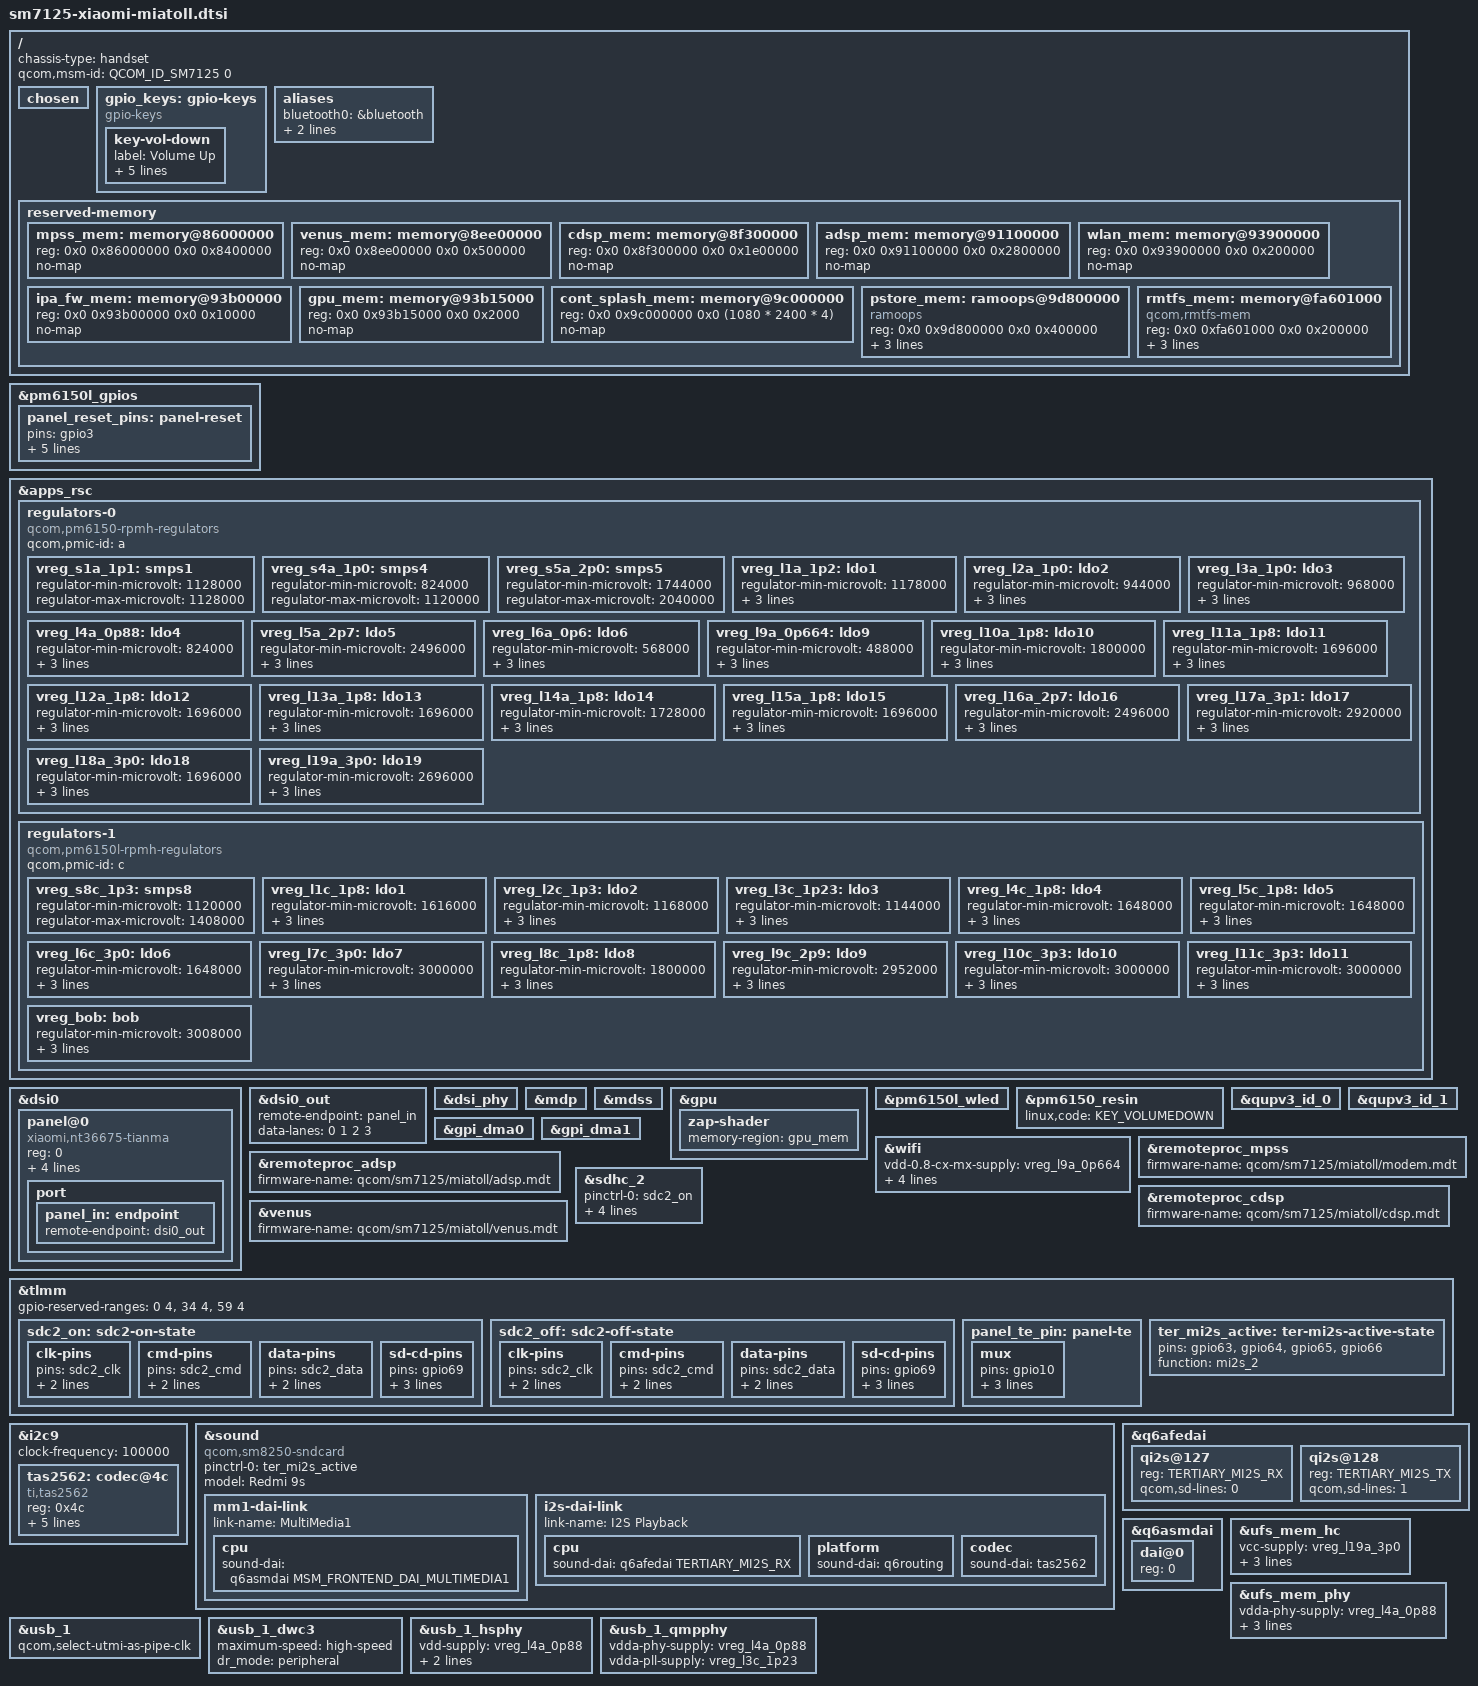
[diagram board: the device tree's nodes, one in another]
// SPDX-License-Identifier: GPL-2.0
/*
 * Copyright (c) 2023, David Wronek <davidwronek@gmail.com>
 */

/dts-v1/;

#include <dt-bindings/arm/qcom,ids.h>
#include <dt-bindings/gpio/gpio.h>
#include <dt-bindings/regulator/qcom,rpmh-regulator.h>
#include <dt-bindings/pinctrl/qcom,pmic-gpio.h>
#include <dt-bindings/sound/qcom,q6asm.h>
#include "sm7125.dtsi"
#include "pm6150.dtsi"
#include "pm6150l.dtsi"

/delete-node/ &ipa_fw_mem;
/delete-node/ &rmtfs_mem;

/ {
	chassis-type = "handset";

	qcom,msm-id = <QCOM_ID_SM7125 0>;

	chosen {
		#address-cells = <2>;
		#size-cells = <2>;
		ranges;
	};

	gpio_keys: gpio-keys {
		compatible = "gpio-keys";

		key-vol-down {
			label = "Volume Up";
			linux,code = <KEY_VOLUMEUP>;
			gpios = <&pm6150l_gpios 2 GPIO_ACTIVE_LOW>;
			debounce-interval = <15>;
			linux,can-disable;
			wakeup-source;
		};
	};

	aliases {
		bluetooth0 = &bluetooth;
		hsuart0 = &uart3;
		wifi0 = &wifi;
	};

	reserved-memory {
		mpss_mem: memory@86000000 {
			reg = <0x0 0x86000000 0x0 0x8400000>;
			no-map;
		};

		venus_mem: memory@8ee00000 {
			reg = <0x0 0x8ee00000 0x0 0x500000>;
			no-map;
		};

		cdsp_mem: memory@8f300000 {
			reg = <0x0 0x8f300000 0x0 0x1e00000>;
			no-map;
		};

		adsp_mem: memory@91100000 {
			reg = <0x0 0x91100000 0x0 0x2800000>;
			no-map;
		};

		wlan_mem: memory@93900000 {
			reg = <0x0 0x93900000 0x0 0x200000>;
			no-map;
		};

		ipa_fw_mem: memory@93b00000 {
			reg = <0x0 0x93b00000 0x0 0x10000>;
			no-map;
		};

		gpu_mem: memory@93b15000 {
			reg = <0x0 0x93b15000 0x0 0x2000>;
			no-map;
		};

		cont_splash_mem: memory@9c000000 {
			reg = <0x0 0x9c000000 0x0 (1080 * 2400 * 4)>;
			no-map;
		};

		pstore_mem: ramoops@9d800000 {
		    compatible = "ramoops";
		    reg = <0x0 0x9d800000 0x0 0x400000>;
		    record-size = <0x80000>;
		    pmsg-size = <0x200000>;
		    console-size = <0x100000>;
		};

		rmtfs_mem: memory@fa601000 {
			compatible = "qcom,rmtfs-mem";
			reg = <0x0 0xfa601000 0x0 0x200000>;
			no-map;

			qcom,client-id = <1>;
			qcom,vmid = <15>;
		};
	};
};

&pm6150l_gpios {
	panel_reset_pins: panel-reset{
		pins = "gpio3";
		function = "func1";
		qcom,drive-strength = <2>;
		power-source = <0>;
		bias-disable;
		output-low;
	};
};

&apps_rsc {
	regulators-0 {
		compatible = "qcom,pm6150-rpmh-regulators";
		qcom,pmic-id = "a";

		vreg_s1a_1p1: smps1 {
			regulator-min-microvolt = <1128000>;
			regulator-max-microvolt = <1128000>;
		};

		vreg_s4a_1p0: smps4 {
			regulator-min-microvolt = <824000>;
			regulator-max-microvolt = <1120000>;
		};

		vreg_s5a_2p0: smps5 {
			regulator-min-microvolt = <1744000>;
			regulator-max-microvolt = <2040000>;
		};

		vreg_l1a_1p2: ldo1 {
			regulator-min-microvolt = <1178000>;
			regulator-max-microvolt = <1256000>;
			regulator-initial-mode = <RPMH_REGULATOR_MODE_LPM>;
		};

		vreg_l2a_1p0: ldo2 {
			regulator-min-microvolt = <944000>;
			regulator-max-microvolt = <1056000>;
			regulator-initial-mode = <RPMH_REGULATOR_MODE_LPM>;
		};

		vreg_l3a_1p0: ldo3 {
			regulator-min-microvolt = <968000>;
			regulator-max-microvolt = <1064000>;
			regulator-initial-mode = <RPMH_REGULATOR_MODE_LPM>;
		};

		vreg_l4a_0p88: ldo4 {
			regulator-min-microvolt = <824000>;
			regulator-max-microvolt = <928000>;
			regulator-initial-mode = <RPMH_REGULATOR_MODE_LPM>;
		};

		vreg_l5a_2p7: ldo5 {
			regulator-min-microvolt = <2496000>;
			regulator-max-microvolt = <3000000>;
			regulator-initial-mode = <RPMH_REGULATOR_MODE_LPM>;
		};

		vreg_l6a_0p6: ldo6 {
			regulator-min-microvolt = <568000>;
			regulator-max-microvolt = <648000>;
			regulator-initial-mode = <RPMH_REGULATOR_MODE_LPM>;
		};

		vreg_l9a_0p664: ldo9 {
			regulator-min-microvolt = <488000>;
			regulator-max-microvolt = <800000>;
			regulator-initial-mode = <RPMH_REGULATOR_MODE_LPM>;
		};

		vreg_l10a_1p8: ldo10 {
			regulator-min-microvolt = <1800000>;
			regulator-max-microvolt = <1832000>;
			regulator-initial-mode = <RPMH_REGULATOR_MODE_LPM>;
		};

		vreg_l11a_1p8: ldo11 {
			regulator-min-microvolt = <1696000>;
			regulator-max-microvolt = <1904000>;
			regulator-initial-mode = <RPMH_REGULATOR_MODE_LPM>;
		};

		vreg_l12a_1p8: ldo12 {
			regulator-min-microvolt = <1696000>;
			regulator-max-microvolt = <1952000>;
			regulator-initial-mode = <RPMH_REGULATOR_MODE_HPM>;
		};

		vreg_l13a_1p8: ldo13 {
			regulator-min-microvolt = <1696000>;
			regulator-max-microvolt = <1904000>;
			regulator-initial-mode = <RPMH_REGULATOR_MODE_LPM>;
		};

		vreg_l14a_1p8: ldo14 {
			regulator-min-microvolt = <1728000>;
			regulator-max-microvolt = <1832000>;
			regulator-initial-mode = <RPMH_REGULATOR_MODE_LPM>;
		};

		vreg_l15a_1p8: ldo15 {
			regulator-min-microvolt = <1696000>;
			regulator-max-microvolt = <1904000>;
			regulator-initial-mode = <RPMH_REGULATOR_MODE_LPM>;
		};

		vreg_l16a_2p7: ldo16 {
			regulator-min-microvolt = <2496000>;
			regulator-max-microvolt = <3304000>;
			regulator-initial-mode = <RPMH_REGULATOR_MODE_LPM>;
		};

		vreg_l17a_3p1: ldo17 {
			regulator-min-microvolt = <2920000>;
			regulator-max-microvolt = <3232000>;
			regulator-initial-mode = <RPMH_REGULATOR_MODE_LPM>;
		};

		vreg_l18a_3p0: ldo18 {
			regulator-min-microvolt = <1696000>;
			regulator-max-microvolt = <1904000>;
			regulator-initial-mode = <RPMH_REGULATOR_MODE_LPM>;
		};

		vreg_l19a_3p0: ldo19 {
			regulator-min-microvolt = <2696000>;
			regulator-max-microvolt = <3304000>;
			regulator-initial-mode = <RPMH_REGULATOR_MODE_HPM>;
		};
	};

	regulators-1 {
		compatible = "qcom,pm6150l-rpmh-regulators";
		qcom,pmic-id = "c";

		vreg_s8c_1p3: smps8 {
			regulator-min-microvolt = <1120000>;
			regulator-max-microvolt = <1408000>;
		};

		vreg_l1c_1p8: ldo1 {
			regulator-min-microvolt = <1616000>;
			regulator-max-microvolt = <1984000>;
			regulator-initial-mode = <RPMH_REGULATOR_MODE_LPM>;
		};

		vreg_l2c_1p3: ldo2 {
			regulator-min-microvolt = <1168000>;
			regulator-max-microvolt = <1304000>;
			regulator-initial-mode = <RPMH_REGULATOR_MODE_LPM>;
		};

		vreg_l3c_1p23: ldo3 {
			regulator-min-microvolt = <1144000>;
			regulator-max-microvolt = <1304000>;
			regulator-initial-mode = <RPMH_REGULATOR_MODE_LPM>;
		};

		vreg_l4c_1p8: ldo4 {
			regulator-min-microvolt = <1648000>;
			regulator-max-microvolt = <3304000>;
			regulator-initial-mode = <RPMH_REGULATOR_MODE_LPM>;
		};

		vreg_l5c_1p8: ldo5 {
			regulator-min-microvolt = <1648000>;
			regulator-max-microvolt = <3304000>;
			regulator-initial-mode = <RPMH_REGULATOR_MODE_LPM>;
		};

		vreg_l6c_3p0: ldo6 {
			regulator-min-microvolt = <1648000>;
			regulator-max-microvolt = <3304000>;
			regulator-initial-mode = <RPMH_REGULATOR_MODE_HPM>;
		};

		vreg_l7c_3p0: ldo7 {
			regulator-min-microvolt = <3000000>;
			regulator-max-microvolt = <3312000>;
			regulator-initial-mode = <RPMH_REGULATOR_MODE_LPM>;
		};

		vreg_l8c_1p8: ldo8 {
			regulator-min-microvolt = <1800000>;
			regulator-max-microvolt = <1904000>;
			regulator-initial-mode = <RPMH_REGULATOR_MODE_LPM>;
		};

		vreg_l9c_2p9: ldo9 {
			regulator-min-microvolt = <2952000>;
			regulator-max-microvolt = <3304000>;
			regulator-initial-mode = <RPMH_REGULATOR_MODE_HPM>;
		};

		vreg_l10c_3p3: ldo10 {
			regulator-min-microvolt = <3000000>;
			regulator-max-microvolt = <3400000>;
			regulator-initial-mode = <RPMH_REGULATOR_MODE_LPM>;
		};

		vreg_l11c_3p3: ldo11 {
			regulator-min-microvolt = <3000000>;
			regulator-max-microvolt = <3400000>;
			regulator-initial-mode = <RPMH_REGULATOR_MODE_LPM>;
		};

		vreg_bob: bob {
			regulator-min-microvolt = <3008000>;
			regulator-max-microvolt = <3960000>;
			regulator-initial-mode = <RPMH_REGULATOR_MODE_AUTO>;
		};
	};
};

&dsi0 {
	status = "okay";

	panel@0 {
		compatible = "xiaomi,nt36675-tianma";
		reg = <0>;

		backlight = <&pm6150l_wled>;

		vddio-supply = <&vreg_l18a_3p0>;

		reset-gpios = <&pm6150l_gpios 3 GPIO_ACTIVE_LOW>;

		pinctrl-names = "default";
		pinctrl-0 = <&panel_reset_pins &panel_te_pin>;

		port {
			panel_in: endpoint {
				remote-endpoint = <&dsi0_out>;
			};
		};
	};
};

&dsi0_out {
	remote-endpoint = <&panel_in>;
	data-lanes = <0 1 2 3>;
};

&dsi_phy {
	status = "okay";
};

&mdp {
	status = "okay";
};

&mdss {
	status = "okay";
};

&gpu {
	status = "okay";

	zap-shader {
		memory-region = <&gpu_mem>;
	};
};

&pm6150l_wled {
 	status = "okay";
};

&pm6150_resin {
    linux,code = <KEY_VOLUMEDOWN>;
    status = "okay";
};

&qupv3_id_0 {
	status = "okay";
};

&qupv3_id_1 {
	status = "okay";
};

&gpi_dma0 {
	status = "okay";
};

&gpi_dma1 {
	status = "okay";
};

&wifi {
	status = "okay";

	vdd-0.8-cx-mx-supply = <&vreg_l9a_0p664>;
	vdd-1.8-xo-supply = <&vreg_l1c_1p8>;
	vdd-1.3-rfa-supply = <&vreg_l2c_1p3>;
	vdd-3.3-ch0-supply = <&vreg_l10c_3p3>;
	vdd-3.3-ch1-supply = <&vreg_l11c_3p3>;
};

&remoteproc_mpss {
	status = "okay";
	firmware-name = "qcom/sm7125/miatoll/modem.mdt";
};

&remoteproc_adsp {
	status = "okay";
	firmware-name = "qcom/sm7125/miatoll/adsp.mdt";
};

&remoteproc_cdsp {
	status = "okay";
	firmware-name = "qcom/sm7125/miatoll/cdsp.mdt";
};

&venus {
	firmware-name = "qcom/sm7125/miatoll/venus.mdt";
};

&sdhc_2 {
	status = "okay";

	pinctrl-names = "default","sleep";
	pinctrl-0 = <&sdc2_on>;
	pinctrl-1 = <&sdc2_off>;
	vmmc-supply = <&vreg_l9c_2p9>;
	vqmmc-supply = <&vreg_l6c_3p0>;

	cd-gpios = <&tlmm 69 GPIO_ACTIVE_HIGH>;
};

&tlmm {
	gpio-reserved-ranges = <0 4>, <34 4>, <59 4>;

	sdc2_on: sdc2-on-state {
		clk-pins {
			pins = "sdc2_clk";
			bias-disable;
			drive-strength = <16>;
		};

		cmd-pins {
			pins = "sdc2_cmd";
			bias-pull-up;
			drive-strength = <10>;
		};

		data-pins {
			pins = "sdc2_data";
			bias-pull-up;
			drive-strength = <10>;
		};

		sd-cd-pins {
			pins = "gpio69";
			function = "gpio";
			bias-pull-up;
			drive-strength = <2>;
		};
	};

	sdc2_off: sdc2-off-state {
		clk-pins {
			pins = "sdc2_clk";
			bias-disable;
			drive-strength = <2>;
		};

		cmd-pins {
			pins = "sdc2_cmd";
			bias-pull-up;
			drive-strength = <2>;
		};

		data-pins {
			pins = "sdc2_data";
			bias-pull-up;
			drive-strength = <2>;
		};

		sd-cd-pins {
			pins = "gpio69";
			function = "gpio";
			bias-pull-up;
			drive-strength = <2>;
		};
	};

	panel_te_pin: panel-te {
		mux {
			pins = "gpio10";
			function = "mdp_vsync";
			drive-strength = <2>;
			bias-pull-down;
		};
	};
	
	ter_mi2s_active: ter-mi2s-active-state {
		pins = "gpio63", "gpio64", "gpio65", "gpio66";
		function = "mi2s_2";
	};
};

&i2c9 {
	status = "okay";
	clock-frequency = <100000>;
	tas2562: codec@4c {
			compatible = "ti,tas2562";
			reg = <0x4c>;
			#sound-dai-cells = <0>;
			interrupt-parent = <&tlmm>;
			interrupts = <33 0>;
			shutdown-gpios = <&tlmm 51 0>;
			ti,vmon-slot-no = <2>;
			ti,imon-slot-no = <0>;
	};
};

&sound {
	compatible = "qcom,sm8250-sndcard";
	pinctrl-0 = <&ter_mi2s_active>;
	pinctrl-names = "default";
	model = "Redmi 9s";

	mm1-dai-link {
		link-name = "MultiMedia1";
		cpu {
			sound-dai = <&q6asmdai MSM_FRONTEND_DAI_MULTIMEDIA1>;
		};
	};

	i2s-dai-link {
		link-name = "I2S Playback";
		cpu {
			sound-dai = <&q6afedai TERTIARY_MI2S_RX>;
		};

		platform {
			sound-dai = <&q6routing>;
		};

		codec {
			sound-dai = <&tas2562>;
		};
	};
};

&q6afedai {
	qi2s@127 {
		reg = <TERTIARY_MI2S_RX>;
		qcom,sd-lines = <0>;
	};

	qi2s@128 {
		reg = <TERTIARY_MI2S_TX>;
		qcom,sd-lines = <1>;
	};
};

&q6asmdai {
	dai@0 {
		reg = <0>;
	};
};

&ufs_mem_hc {
	vcc-supply = <&vreg_l19a_3p0>;
	vcc-max-microamp = <600000>;
	vccq2-supply = <&vreg_l12a_1p8>;
	vccq2-max-microamp = <600000>;
	status = "okay";
};

&ufs_mem_phy {
	vdda-phy-supply = <&vreg_l4a_0p88>;
	vdda-pll-supply = <&vreg_l3c_1p23>;
	vdda-phy-max-microamp = <62900>;
	vdda-pll-max-microamp = <18300>;
	status = "okay";
};

&usb_1 {
	qcom,select-utmi-as-pipe-clk;
	status = "okay";
};

&usb_1_dwc3 {
	maximum-speed = "high-speed";
	dr_mode = "peripheral";
	status = "okay";
};

&usb_1_hsphy {
	vdd-supply = <&vreg_l4a_0p88>;
	vdda-pll-supply = <&vreg_l11a_1p8>;
	vdda-phy-dpdm-supply = <&vreg_l17a_3p1>;
	status = "okay";
};

&usb_1_qmpphy {
	status = "okay";
	vdda-phy-supply = <&vreg_l4a_0p88>;
	vdda-pll-supply = <&vreg_l3c_1p23>;
};
